# VPAC0_PAR_VPAC_VISS0_S_VBUSP_MMR_CFG_VISS_TOP register map
Vendor: Texas Instruments
Peripheral module from a debugger description file (folder J7ES).
Registers are 32-bit, read-write, reset 0x0 unless marked. A register's access mark holds for its fields unless they carry their own. Offsets are as the file gives them; lines under a group give offsets from that group; [hi:lo] are bit positions; {n}, {i} and the like mark numbered series; 'fields as' and 'values as' point back to an identical list; <NAME> marks a mode.

## VPAC0_PAR_VPAC_VISS0_S_VBUSP_MMR_CFG_VISS_TOP
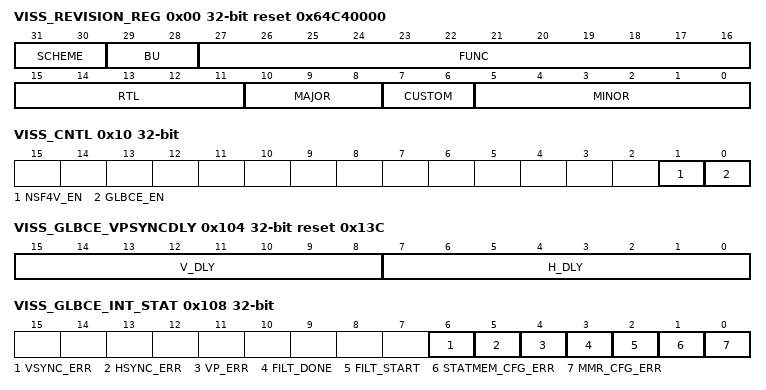
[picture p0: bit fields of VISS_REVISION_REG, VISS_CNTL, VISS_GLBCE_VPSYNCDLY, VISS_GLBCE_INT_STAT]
0x00 VISS_REVISION_REG ro reset 0x64C40000 — VISS PID
  [31:30] SCHEME — Used to distinguish between old scheme and new scheme.
  [29:28] BU — BU indicator DSPS ==&gt; 0x0 WTBU ==&gt; 0x1 Processors ==&gt; 0x2
  [27:16] FUNC — Function indicates a software compatible module family.
  [15:11] RTL — RTL Version.
  [10:8] MAJOR — Major Revision.
  [7:6] CUSTOM — Indicates a special version for a particular device.
  [5:0] MINOR — Minor Revision.
0x08 VISS_LINEMEM_SIZE ro reset 0x1000 — Captures the no. of pixels per line supported by the VISS
  [13:0] LINEMEM_SZ — No.
0x10 VISS_CNTL — VISS top control
  [1] NSF4V_EN — '1' -&gt; NSF4V is ON , '0' -&gt; NSF4V is off i.e.
  [0] GLBCE_EN — '1' -&gt; GLBCE is ON , '0' -&gt; GLBCE is off i.e.
0x80 VISS_DBG_CTL — Enable for VISS debug staus capture
  [1] PRTL_WR_EN — Enable to Capture Partial Write to any VISS end point
0x84 VISS_DBG_STAT access not given — Set/Clear for VISS debug status
  [1] PRTL_WR — Status/Clear for Partial Write to any VISS end point. (access RW1C)
0x100 VISS_GLBCECONFIG — GLBCE Configuration
  [0] GLBCE_PCLKFREE — '1'-&gt; GLBCE pclk is free running , '0' -&gt; GLBCE pclk is gated pixel clock
0x104 VISS_GLBCE_VPSYNCDLY reset 0x13C — Delay of GLBCE Core, used to regenerate VS/VE VPORT signals
  [15:8] V_DLY — Line delay between GLBCE.VS_In to GLBCE.VS_Out
  [7:0] H_DLY — Cycle delay between GLBCE.HS_In to GLBCE.HS_Out minus 1
0x108 VISS_GLBCE_INT_STAT access not given — Set on internal interutp event and clr by SW
  [6] VSYNC_ERR — status/clear for GLBCE VSYNC Delay programmation error. (access RW1C)
  [5] HSYNC_ERR — status/clear for GLBCE HSYNC Delay programmation error. (access RW1C)
  [4] VP_ERR — status/clear for GLBCE Input frame start error. (access RW1C)
  [3] FILT_DONE — status/clear for GLBCE Filtering Done event. (access RW1C)
  [2] FILT_START — status/clear for GLBCE Filtering Start event. (access RW1C)
  [1] STATMEM_CFG_ERR — status/clear for statastics memory configuration error. (access RW1C)
  [0] MMR_CFG_ERR — status/clear for mmr configuration error. (access RW1C)
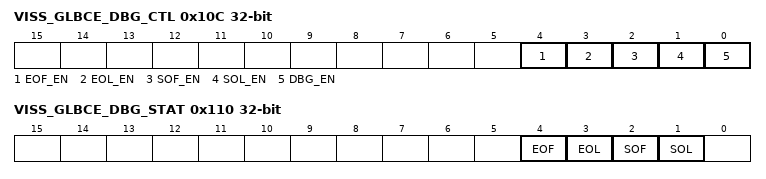
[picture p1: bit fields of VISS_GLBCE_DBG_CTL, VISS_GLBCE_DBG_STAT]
0x10C VISS_GLBCE_DBG_CTL — Enable for GLBCE debug events
  [4] EOF_EN — Enable for EOF at GLBCE output
  [3] EOL_EN — Enable for EOF at GLBCE output
  [2] SOF_EN — Enable for SOF at GLBCE input
  [1] SOL_EN — Enable for SOL at GLBCE input
  [0] DBG_EN — Enable debug features, set to '0' to disable all debug events
0x110 VISS_GLBCE_DBG_STAT access not given — Set/Clear for GLBCE debug events
  [4] EOF — Status/Clear for EOF at GLBCE output. (access RW1C)
  [3] EOL — Status/Clear for EOF at GLBCE output. (access RW1C)
  [2] SOF — Status/Clear for SOF at GLBCE input. (access RW1C)
  [1] SOL — Status/Clear for SOL at GLBCE input. (access RW1C)
